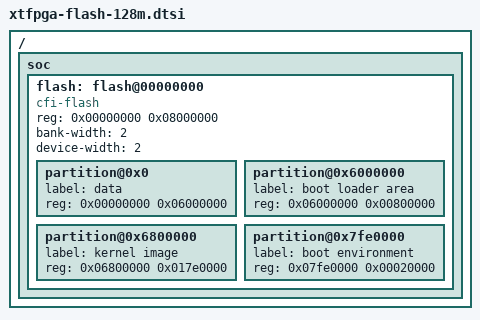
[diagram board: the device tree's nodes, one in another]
// SPDX-License-Identifier: GPL-2.0
/ {
	soc {
		flash: flash@00000000 {
			#address-cells = <1>;
			#size-cells = <1>;
			compatible = "cfi-flash";
			reg = <0x00000000 0x08000000>;
			bank-width = <2>;
			device-width = <2>;
			partition@0x0 {
				label = "data";
				reg = <0x00000000 0x06000000>;
			};
			partition@0x6000000 {
				label = "boot loader area";
				reg = <0x06000000 0x00800000>;
			};
			partition@0x6800000 {
				label = "kernel image";
				reg = <0x06800000 0x017e0000>;
			};
			partition@0x7fe0000 {
				label = "boot environment";
				reg = <0x07fe0000 0x00020000>;
			};
		};
        };
};
